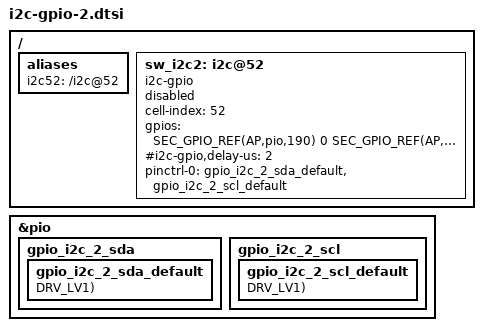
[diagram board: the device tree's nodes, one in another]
&pio {
       gpio_i2c_2_sda {
               gpio_i2c_2_sda_default: gpio_i2c_2_sda_default {
                       GPIO_CONFIG_PUD_DRV(AP,pio,190, FUNC_INPUT, PULL_NONE, DRV_LV1);
               };
       };
};

&pio {
       gpio_i2c_2_scl {
               gpio_i2c_2_scl_default: gpio_i2c_2_scl_default {
                       GPIO_CONFIG_PUD_DRV(AP,pio,189, FUNC_INPUT, PULL_NONE, DRV_LV1);
               };
       };
};

/ {
	fragment@model {
		target-path = "/";
	        __overlay__ {
			aliases {
				  i2c52 = "/i2c@52";
			};
			/* Software I2C */
			sw_i2c2: i2c@52 {
				cell-index = <52>;
				compatible = "i2c-gpio";
				gpios = <
					SEC_GPIO_REF(AP,pio,190) 0 /* SDA */
					SEC_GPIO_REF(AP,pio,189) 0 /* SCL */
					>;
				#i2c-gpio,delay-us = <2>;
				#address-cells = <1>;
				#size-cells = <0>;

				pinctrl-names = "default";
				pinctrl-0 = <
					&gpio_i2c_2_sda_default
					&gpio_i2c_2_scl_default
					>;

				status = "disabled";
			};
		};
	};
};

